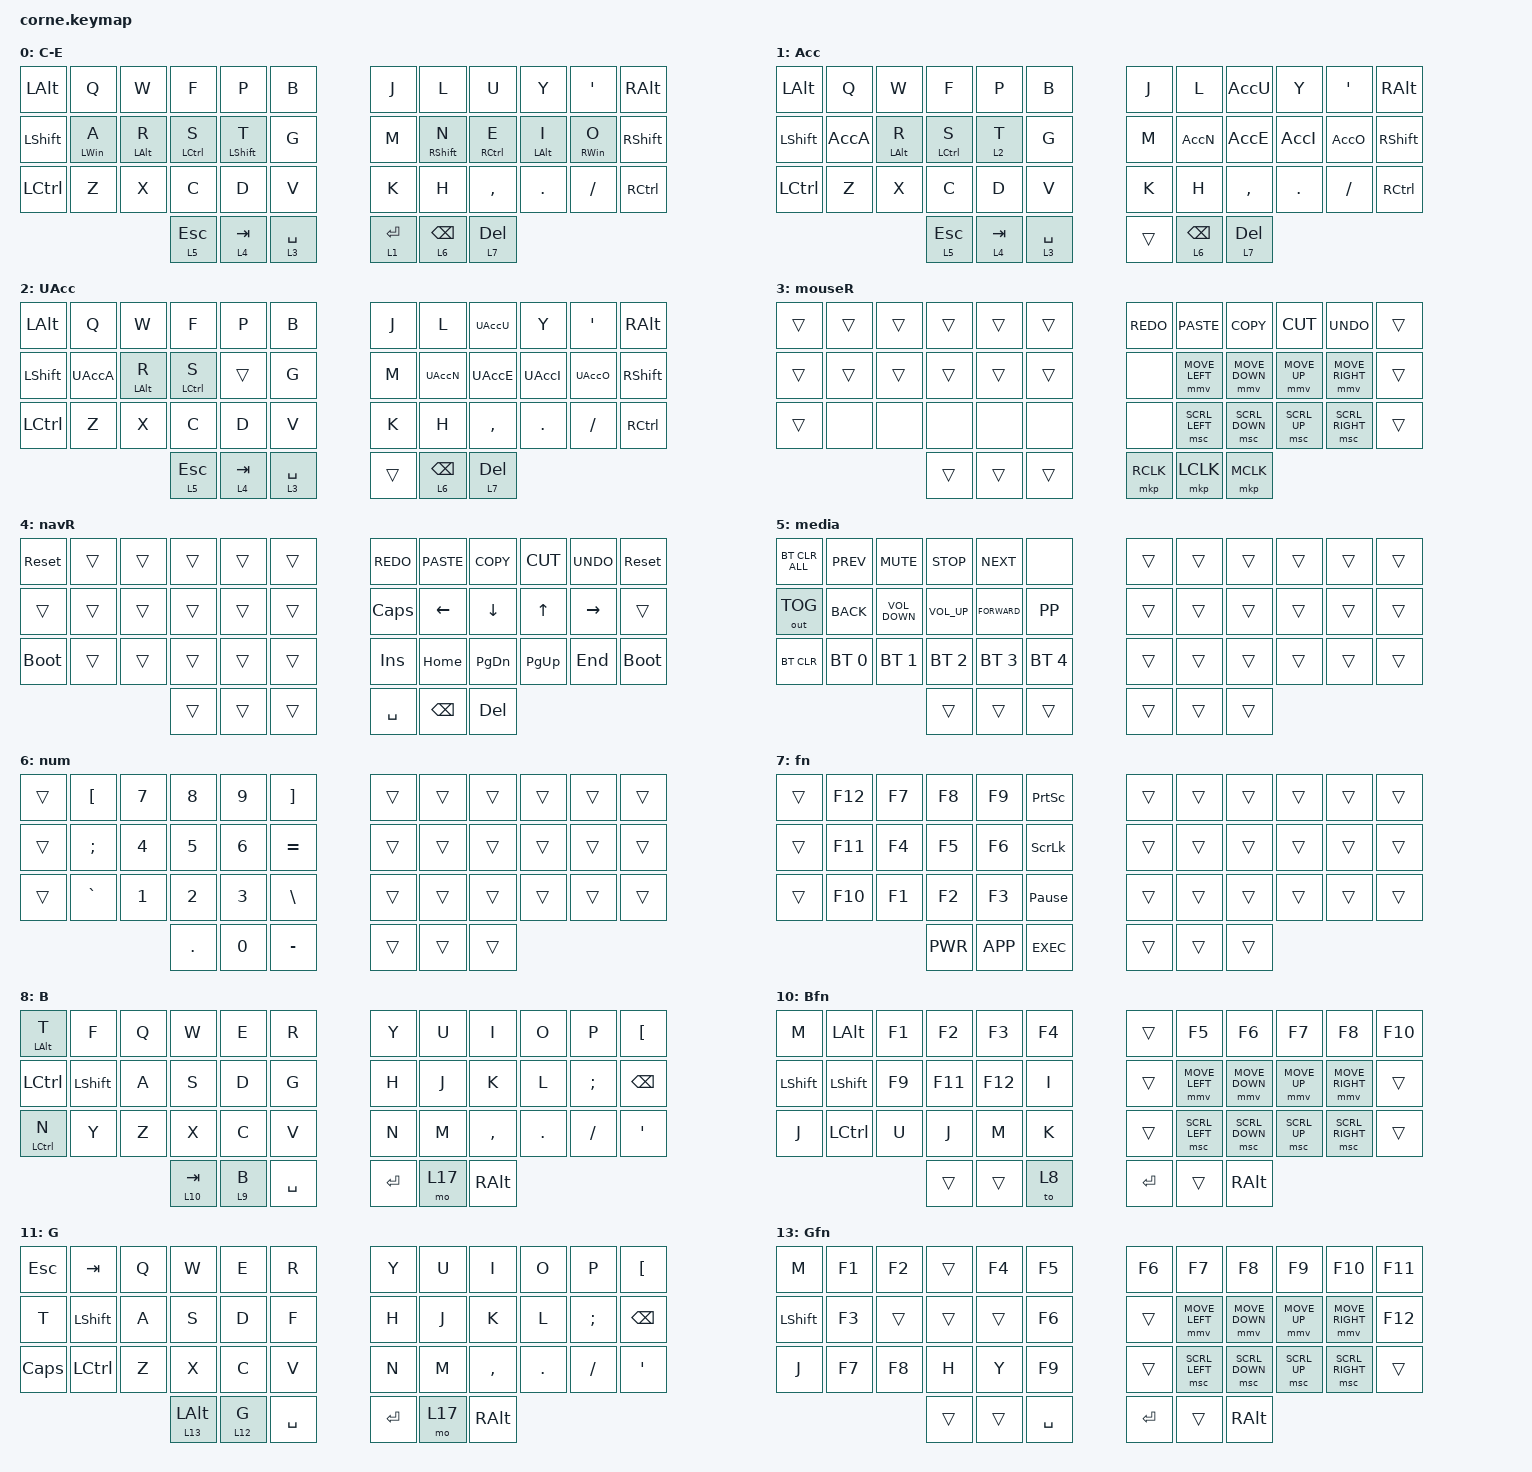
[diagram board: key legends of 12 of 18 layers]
/*
 * Copyright (c) 2020 The ZMK Contributors
 *
 * SPDX-License-Identifier: MIT
 */

#include <behaviors.dtsi>
#include <dt-bindings/zmk/bt.h>
#include <dt-bindings/zmk/ext_power.h>
#include <dt-bindings/zmk/keys.h>
#include <dt-bindings/zmk/outputs.h>
#include <dt-bindings/zmk/pointing.h>

#define ZMK_POINTING_DEFAULT_MOVE_VAL 1200  // default: 600
#define ZMK_POINTING_DEFAULT_SCRL_VAL 20    // default: 10

/ {
    combos {
        compatible = "zmk,combos";

        Game {
            bindings = <&to 11>;
            key-positions = <40 41>;
            layers = <0 14 8 15 16 6>;
        };

        Qwerty {
            bindings = <&to 14>;
            key-positions = <41 36>;
            layers = <0 11 8 6 15 16>;
        };

        Blender {
            bindings = <&to 8>;
            key-positions = <36 38>;
            layers = <14 0 11 6 15 16 9 10>;
        };

        altEsc {
            bindings = <&kp ESCAPE>;
            key-positions = <1 2>;
            layers = <14 8 9 10>;
        };

        altDel {
            bindings = <&kp BACKSPACE>;
            key-positions = <9 10>;
            layers = <14>;
        };

        altEntr {
            bindings = <&kp ENTER>;
            key-positions = <22 21>;
            layers = <14>;
        };

        colemak {
            bindings = <&to 0>;
            key-positions = <36 37>;
            layers = <14 11 6 15 16 8 9 12>;
        };

        Num {
            bindings = <&to 6>;
            key-positions = <12 0>;
            layers = <14 11 0 16 15 8 9 10>;
        };

        Mouse {
            bindings = <&to 16>;
            key-positions = <38 24>;
            layers = <14 11 0 6 15 8 9 10>;
        };

        Nav {
            bindings = <&to 15>;
            key-positions = <37 24>;
            layers = <14 11 0 6 16 8 9 10>;
        };

        altSup {
            bindings = <&kp DEL>;
            key-positions = <25 26>;
            layers = <8 9 10>;
        };

        BNum {
            bindings = <&to 9>;
            key-positions = <37 25>;
            layers = <6 15 16 8 10>;
        };

        BFn {
            bindings = <&to 10>;
            key-positions = <37 26>;
            layers = <6 15 16 8 9>;
        };

        STR {
            bindings = <&ext_power EP_TOG>;
            key-positions = <35 23 11>;
        };

        STL {
            bindings = <&ext_power EP_TOG>;
            key-positions = <24 0 12>;
        };
    };

    behaviors {
        HMR: HMR {
            compatible = "zmk,behavior-hold-tap";
            label = "HMR";
            bindings = <&kp>, <&kp>;

            #binding-cells = <2>;
            tapping-term-ms = <280>;
            quick-tap-ms = <175>;
            flavor = "tap-preferred";
            hold-trigger-on-release;
            hold-trigger-key-positions = <0 1 2 3 4 5 12 13 14 15 16 17 24 25 26 27 28 29 36 37 38 39 40 41>;
        };

        HML: HML {
            compatible = "zmk,behavior-hold-tap";
            label = "HML";
            bindings = <&kp>, <&kp>;

            #binding-cells = <2>;
            tapping-term-ms = <280>;
            quick-tap-ms = <175>;
            hold-trigger-on-release;
            hold-trigger-key-positions = <6 7 8 9 10 11 18 19 20 21 22 23 30 31 32 33 34 35 39 40 41 36 37 38>;
            flavor = "tap-preferred";
        };

        LTM: LTM {
            compatible = "zmk,behavior-hold-tap";
            label = "LTM";
            bindings = <&mo>, <&kp>;

            #binding-cells = <2>;
            tapping-term-ms = <200>;
            quick-tap-ms = <175>;
            hold-trigger-on-release;
            hold-trigger-key-positions = <39 40 41 36 37 38>;
            flavor = "hold-preferred";
        };
    };

    macros {
        AccA: AccA {
            compatible = "zmk,behavior-macro";
            #binding-cells = <0>;
            bindings = <&kp RA(SQT) &kp A>;
            label = "ACCA";
        };

        AccE: AccE {
            compatible = "zmk,behavior-macro";
            #binding-cells = <0>;
            bindings = <&kp RA(SQT) &kp E>;
            label = "ACCE";
        };

        AccI: AccI {
            compatible = "zmk,behavior-macro";
            #binding-cells = <0>;
            bindings = <&kp RA(SQT) &kp I>;
            label = "ACCI";
        };

        AccO: AccO {
            compatible = "zmk,behavior-macro";
            #binding-cells = <0>;
            bindings = <&kp RA(SQT) &kp O>;
            label = "ACCO";
        };

        AccU: AccU {
            compatible = "zmk,behavior-macro";
            #binding-cells = <0>;
            bindings = <&kp RA(SQT) &kp U>;
            label = "ACCU";
        };

        AccN: AccN {
            compatible = "zmk,behavior-macro";
            #binding-cells = <0>;
            bindings = <&kp RA(TILDE) &kp N>;
            label = "ACCN";
        };

        UAccA: UAccA {
            compatible = "zmk,behavior-macro";
            #binding-cells = <0>;
            bindings = <&kp RA(SQT) &kp LS(A)>;
            label = "UACCA";
        };

        UAccE: UAccE {
            compatible = "zmk,behavior-macro";
            #binding-cells = <0>;
            bindings = <&kp RA(SQT) &kp LS(E)>;
            label = "UACCE";
        };

        UAccI: UAccI {
            compatible = "zmk,behavior-macro";
            #binding-cells = <0>;
            bindings = <&kp RA(SQT) &kp LS(I)>;
            label = "UACCI";
        };

        UAccO: UAccO {
            compatible = "zmk,behavior-macro";
            #binding-cells = <0>;
            bindings = <&kp RA(SQT) &kp LS(O)>;
            label = "UACCO";
        };

        UAccU: UAccU {
            compatible = "zmk,behavior-macro";
            #binding-cells = <0>;
            bindings = <&kp RA(SQT) &kp LS(U)>;
            label = "UACCU";
        };

        UAccN: UAccN {
            compatible = "zmk,behavior-macro";
            #binding-cells = <0>;
            bindings = <&kp RA(TILDE) &kp LS(N)>;
            label = "UACCN";
        };
    };

    keymap {
        compatible = "zmk,keymap";

        Colemak-DHm {
            display-name = "C-E";
            bindings = <
&kp LALT    &kp Q        &kp W        &kp F         &kp P          &kp B           &kp J       &kp L          &kp U         &kp Y        &kp SQT      &kp RALT
&kp LSHIFT  &HML LWIN A  &HML LALT R  &HML LCTRL S  &HML LSHIFT T  &kp G           &kp M       &HMR RSHIFT N  &HMR RCTRL E  &HMR LALT I  &HMR RWIN O  &kp RSHIFT
&kp LCTRL   &kp Z        &kp X        &kp C         &kp D          &kp V           &kp K       &kp H          &kp COMMA     &kp DOT      &kp FSLH     &kp RCTRL
                                      &LTM 5 ESC    &LTM 4 TAB     &LTM 3 SPACE    &LTM 1 RET  &LTM 6 BSPC    &LTM 7 DEL
            >;
        };

        Accent {
            display-name = "Acc";
            bindings = <
&kp LALT    &kp Q  &kp W        &kp F         &kp P       &kp B           &kp J   &kp L        &AccU       &kp Y    &kp SQT   &kp RALT
&kp LSHIFT  &AccA  &HML LALT R  &HML LCTRL S  &lt 2 T     &kp G           &kp M   &AccN        &AccE       &AccI    &AccO     &kp RSHIFT
&kp LCTRL   &kp Z  &kp X        &kp C         &kp D       &kp V           &kp K   &kp H        &kp COMMA   &kp DOT  &kp FSLH  &kp RCTRL
                                &LTM 5 ESC    &LTM 4 TAB  &LTM 3 SPACE    &trans  &LTM 6 BSPC  &LTM 7 DEL
            >;
        };

        UpAccent {
            display-name = "UAcc";
            bindings = <
&kp LALT    &kp Q   &kp W        &kp F         &kp P       &kp B           &kp J   &kp L        &UAccU      &kp Y    &kp SQT   &kp RALT
&kp LSHIFT  &UAccA  &HML LALT R  &HML LCTRL S  &trans      &kp G           &kp M   &UAccN       &UAccE      &UAccI   &UAccO    &kp RSHIFT
&kp LCTRL   &kp Z   &kp X        &kp C         &kp D       &kp V           &kp K   &kp H        &kp COMMA   &kp DOT  &kp FSLH  &kp RCTRL
                                 &LTM 5 ESC    &LTM 4 TAB  &LTM 3 SPACE    &trans  &LTM 6 BSPC  &LTM 7 DEL
            >;
        };

        MouseR {
            display-name = "mouseR";
            bindings = <
&trans  &trans  &trans  &trans  &trans  &trans    &kp K_REDO  &kp K_PASTE     &kp K_COPY      &kp K_CUT     &kp K_UNDO       &trans
&trans  &trans  &trans  &trans  &trans  &trans    &none       &mmv MOVE_LEFT  &mmv MOVE_DOWN  &mmv MOVE_UP  &mmv MOVE_RIGHT  &trans
&trans  &none   &none   &none   &none   &none     &none       &msc SCRL_LEFT  &msc SCRL_DOWN  &msc SCRL_UP  &msc SCRL_RIGHT  &trans
                        &trans  &trans  &trans    &mkp RCLK   &mkp LCLK       &mkp MCLK
            >;
        };

        NavR {
            display-name = "navR";
            bindings = <
&sys_reset   &trans  &trans  &trans  &trans  &trans    &kp K_REDO  &kp K_PASTE  &kp K_COPY     &kp K_CUT    &kp K_UNDO  &sys_reset
&trans       &trans  &trans  &trans  &trans  &trans    &kp CAPS    &kp LEFT     &kp DOWN       &kp UP       &kp RIGHT   &trans
&bootloader  &trans  &trans  &trans  &trans  &trans    &kp INSERT  &kp HOME     &kp PAGE_DOWN  &kp PAGE_UP  &kp END     &bootloader
                             &trans  &trans  &trans    &kp SPACE   &kp BSPC     &kp DEL
            >;
        };

        Media {
            display-name = "media";
            bindings = <
&bt BT_CLR_ALL  &kp K_PREV    &kp K_MUTE         &kp K_STOP       &kp K_NEXT     &none           &trans  &trans  &trans  &trans  &trans  &trans
&out OUT_TOG    &kp K_BACK    &kp K_VOLUME_DOWN  &kp K_VOLUME_UP  &kp K_FORWARD  &kp K_PP        &trans  &trans  &trans  &trans  &trans  &trans
&bt BT_CLR      &bt BT_SEL 0  &bt BT_SEL 1       &bt BT_SEL 2     &bt BT_SEL 3   &bt BT_SEL 4    &trans  &trans  &trans  &trans  &trans  &trans
                                                 &trans           &trans         &trans          &trans  &trans  &trans
            >;
        };

        Num {
            // -----------------------------------------------------------------------------------------
            // |  TAB |  1  |  2  |  3  |  4  |  5  |   |  6  |  7  |  8  |  9  |  0  | BKSP |
            // | BTCLR| BT1 | BT2 | BT3 | BT4 | BT5 |   | LFT | DWN |  UP | RGT |     |      |
            // | SHFT |     |     |     |     |     |   |     |     |     |     |     |      |
            //                    | GUI |     | SPC |   | ENT |     | ALT |

            display-name = "num";
            bindings = <
&trans  &kp LBKT   &kp N7  &kp N8   &kp N9  &kp RBKT     &trans  &trans  &trans  &trans  &trans  &trans
&trans  &kp SEMI   &kp N4  &kp N5   &kp N6  &kp EQUAL    &trans  &trans  &trans  &trans  &trans  &trans
&trans  &kp GRAVE  &kp N1  &kp N2   &kp N3  &kp BSLH     &trans  &trans  &trans  &trans  &trans  &trans
                           &kp DOT  &kp N0  &kp MINUS    &trans  &trans  &trans
            >;
        };

        Fn {
            display-name = "fn";
            bindings = <
&trans  &kp F12  &kp F7  &kp F8     &kp F9     &kp PSCRN          &trans  &trans  &trans  &trans  &trans  &trans
&trans  &kp F11  &kp F4  &kp F5     &kp F6     &kp SLCK           &trans  &trans  &trans  &trans  &trans  &trans
&trans  &kp F10  &kp F1  &kp F2     &kp F3     &kp PAUSE_BREAK    &trans  &trans  &trans  &trans  &trans  &trans
                         &kp K_PWR  &kp K_APP  &kp K_EXEC         &trans  &trans  &trans
            >;
        };

        Blender {
            display-name = "B";
            bindings = <
&mt LALT T   &kp F      &kp Q  &kp W        &kp E     &kp R        &kp Y      &kp U   &kp I      &kp O    &kp P          &kp LEFT_BRACKET
&kp LCTRL    &kp LSHFT  &kp A  &kp S        &kp D     &kp G        &kp H      &kp J   &kp K      &kp L    &kp SEMICOLON  &kp BACKSPACE
&mt LCTRL N  &kp Y      &kp Z  &kp X        &kp C     &kp V        &kp N      &kp M   &kp COMMA  &kp DOT  &kp FSLH       &kp APOS
                               &LTM 10 TAB  &LTM 9 B  &kp SPACE    &kp ENTER  &mo 17  &kp RALT
            >;
        };

        BlendNum {
            display-name = "Bnum";
            bindings = <
&kp LALT    &kp N1  &kp KP_N7  &kp KP_N8   &kp KP_N9  &kp P            &kp N6                    &kp N7       &kp N8      &kp N9     &kp N0      &kp BSPC
&kp LSHIFT  &kp N2  &kp KP_N4  &kp KP_N5   &kp KP_N6  &kp L            &kp LS(LC(LG(LEFT_ALT)))  &kp LEFT     &kp DOWN    &kp UP     &kp RIGHT   &kp DELETE
&kp LCTRL   &kp N3  &kp KP_N1  &kp KP_N2   &kp KP_N3  &kp TILDE        &kp K_REDO                &kp K_PASTE  &kp K_COPY  &kp K_CUT  &kp K_UNDO  &trans
                               &kp KP_DOT  &kp KP_N0  &kp KP_DIVIDE    &kp ENTER                 &trans       &kp RALT
            >;
        };

        BlendFn {
            display-name = "Bfn";
            bindings = <
&kp M       &kp LALT    &kp F1  &kp F2   &kp F3   &kp F4    &trans     &kp F5          &kp F6          &kp F7        &kp F8           &kp F10
&kp LSHIFT  &kp LSHIFT  &kp F9  &kp F11  &kp F12  &kp I     &trans     &mmv MOVE_LEFT  &mmv MOVE_DOWN  &mmv MOVE_UP  &mmv MOVE_RIGHT  &trans
&kp J       &kp LCTRL   &kp U   &kp J    &kp M    &kp K     &trans     &msc SCRL_LEFT  &msc SCRL_DOWN  &msc SCRL_UP  &msc SCRL_RIGHT  &trans
                                &trans   &trans   &to 8     &kp ENTER  &trans          &kp RALT
            >;
        };

        qwertyG {
            // -----------------------------------------------------------------------------------------
            // |  TAB |  Q  |  W  |  E  |  R  |  T  |   |  Y  |  U   |  I  |  O  |  P  | BKSP |
            // | CTRL |  A  |  S  |  D  |  F  |  G  |   |  H  |  J   |  K  |  L  |  ;  |  '   |
            // | SHFT |  Z  |  X  |  C  |  V  |  B  |   |  N  |  M   |  ,  |  .  |  /  | ESC  |
            //                    | GUI | LWR | SPC |   | ENT | RSE  | ALT |

            display-name = "G";
            bindings = <
&kp ESC   &kp TAB    &kp Q  &kp W         &kp E      &kp R        &kp Y      &kp U   &kp I      &kp O    &kp P          &kp LEFT_BRACKET
&kp T     &kp LSHFT  &kp A  &kp S         &kp D      &kp F        &kp H      &kp J   &kp K      &kp L    &kp SEMICOLON  &kp BACKSPACE
&kp CAPS  &kp LCTRL  &kp Z  &kp X         &kp C      &kp V        &kp N      &kp M   &kp COMMA  &kp DOT  &kp FSLH       &kp APOS
                            &LTM 13 LALT  &LTM 12 G  &kp SPACE    &kp ENTER  &mo 17  &kp RALT
            >;
        };

        GNum {
            display-name = "Gnum";
            bindings = <
&kp P       &kp N1  &kp N2  &trans  &kp N4  &kp N5       &kp N6                    &kp N7       &kp N8      &kp N9     &kp N0      &kp BSPC
&kp LSHIFT  &kp N3  &trans  &trans  &trans  &kp N6       &kp LS(LC(LG(LEFT_ALT)))  &kp LEFT     &kp DOWN    &kp UP     &kp RIGHT   &kp DELETE
&kp LCTRL   &kp N7  &kp N8  &kp B   &kp N   &kp N9       &kp K_REDO                &kp K_PASTE  &kp K_COPY  &kp K_CUT  &kp K_UNDO  &trans
                            &kp U   &trans  &kp SPACE    &kp ENTER                 &trans       &kp RALT
            >;
        };

        GFn {
            display-name = "Gfn";
            bindings = <
&kp M       &kp F1  &kp F2  &trans  &kp F4  &kp F5       &kp F6     &kp F7          &kp F8          &kp F9        &kp F10          &kp F11
&kp LSHIFT  &kp F3  &trans  &trans  &trans  &kp F6       &trans     &mmv MOVE_LEFT  &mmv MOVE_DOWN  &mmv MOVE_UP  &mmv MOVE_RIGHT  &kp F12
&kp J       &kp F7  &kp F8  &kp H   &kp Y   &kp F9       &trans     &msc SCRL_LEFT  &msc SCRL_DOWN  &msc SCRL_UP  &msc SCRL_RIGHT  &trans
                            &trans  &trans  &kp SPACE    &kp ENTER  &trans          &kp RALT
            >;
        };

        qwerty {
            display-name = "Q";
            bindings = <
&kp ESC           &kp Q  &kp W  &kp E            &kp R       &kp T           &kp Y      &kp U       &kp I        &kp O    &kp P     &kp LEFT_BRACKET
&kp LEFT_SHIFT    &kp A  &kp S  &kp D            &kp F       &kp G           &kp H      &kp J       &kp K        &kp L    &kp SEMI  &kp BACKSPACE
&kp LEFT_CONTROL  &kp Z  &kp X  &kp C            &kp V       &kp B           &kp N      &kp M       &kp COMMA    &kp DOT  &kp FSLH  &kp APOS
                                &LTM 5 LEFT_WIN  &LTM 4 TAB  &LTM 3 ENTER    &kp SPACE  &LTM 6 DEL  &LTM 7 RALT
            >;
        };

        Nav {
            display-name = "nav";
            bindings = <
&sys_reset   &kp K_UNDO  &kp K_CUT  &kp K_COPY  &kp K_PASTE  &kp K_REDO    &trans     &trans    &trans   &trans  &trans  &sys_reset
&trans       &kp LEFT    &kp UP     &kp DOWN    &kp RIGHT    &kp CAPS      &trans     &trans    &trans   &trans  &trans  &trans
&bootloader  &kp END     &kp PG_UP  &kp PG_DN   &kp HOME     &kp INS       &trans     &trans    &trans   &trans  &trans  &bootloader
                                    &trans      &trans       &trans        &kp SPACE  &kp BSPC  &kp DEL
            >;
        };

        Mouse {
            display-name = "mouse";
            bindings = <
&trans  &kp K_UNDO      &kp K_CUT     &kp K_COPY      &kp K_PASTE      &kp K_REDO    &trans     &trans     &trans     &trans  &trans  &trans
&trans  &mmv MOVE_LEFT  &mmv MOVE_UP  &mmv MOVE_DOWN  &mmv MOVE_RIGHT  &mkp LCLK     &trans     &trans     &trans     &trans  &trans  &trans
&trans  &msc SCRL_LEFT  &msc SCRL_UP  &msc SCRL_DOWN  &msc SCRL_RIGHT  &mkp RCLK     &trans     &trans     &trans     &trans  &trans  &trans
                                      &mkp MCLK       &mkp LCLK        &mkp RCLK     &mkp RCLK  &mkp LCLK  &mkp MCLK
            >;
        };

        MediaR {
            display-name = "mediaR";
            bindings = <
&bt BT_CLR_ALL  &trans        &trans        &trans        &trans        &trans          &none       &none       &none         &none         &none          &none
&out OUT_TOG    &trans        &trans        &trans        &trans        &trans          &none       &kp K_PREV  &kp K_VOL_DN  &kp K_VOL_UP  &kp K_NEXT     &none
&bt BT_CLR      &bt BT_SEL 0  &bt BT_SEL 1  &bt BT_SEL 2  &bt BT_SEL 3  &bt BT_SEL 4    &none       &kp K_BACK  &none         &none         &kp K_FORWARD  &none
                                            &trans        &trans        &trans          &kp K_STOP  &kp K_PP    &kp K_MUTE
            >;
        };
    };
};
